# GD32E25x register map
File version: 1.0
CPU: CM23 r1p0, little endian, no MPU, no FPU, 2 interrupt priority bits
Registers are 32-bit, read-write, reset 0x0 unless marked. A register's access mark holds for its fields unless they carry their own. Offsets are from the block's base; [hi:lo] are bit positions.

## CMP — Comparator
Base 0x4001001C
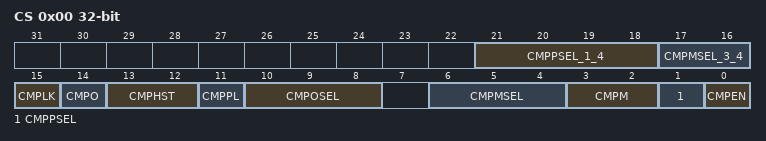
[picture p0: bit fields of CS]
0x00 CS access per field — control and status register
  [21:18] CMPPSEL_1_4 rw — CMP_IM input selection
  [17:16] CMPMSEL_3_4 rw — CMP_IP input selection
  [15] CMPLK rw — Comparator lock
  [14] CMPO ro — Comparator output
  [13:12] CMPHST rw — Comparator hysteresis
  [11] CMPPL rw — Polarity of comparator output
  [10:8] CMPOSEL rw — Comparator output selection
  [6:4] CMPMSEL rw — Comparator input selection
  [3:2] CMPM rw — Comparator mode
  [1] CMPPSEL rw — Comparator switch
  [0] CMPEN rw — Comparator enable

## CRC — cyclic redundancy check calculation unit
Base 0x40023000
0x00 DATA reset 0xFFFFFFFF
  [31:0] DATA — CRC calculation result bits
0x04 FDATA — Free data register
  [7:0] FDATA — General-purpose 8-bit data register bits
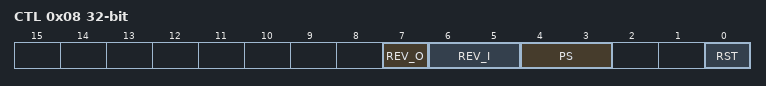
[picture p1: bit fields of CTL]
0x08 CTL — Control register
  [7] REV_O — Reverse output data
  [6:5] REV_I — Reverse input data
  [4:3] PS — Size of polynomial
  [0] RST — reset bit
0x10 IDATA reset 0xFFFFFFFF — Initialization Data Register
  [31:0] IDATA — CRC calculation initial value
0x14 POLY reset 0x4C11DB7 — Polynomial register
  [31:0] POLY — User configurable polynomial value

## DAC0 — Digital-to-analog converter
Base 0x40007400
Same registers: DAC1 0x4000CC00
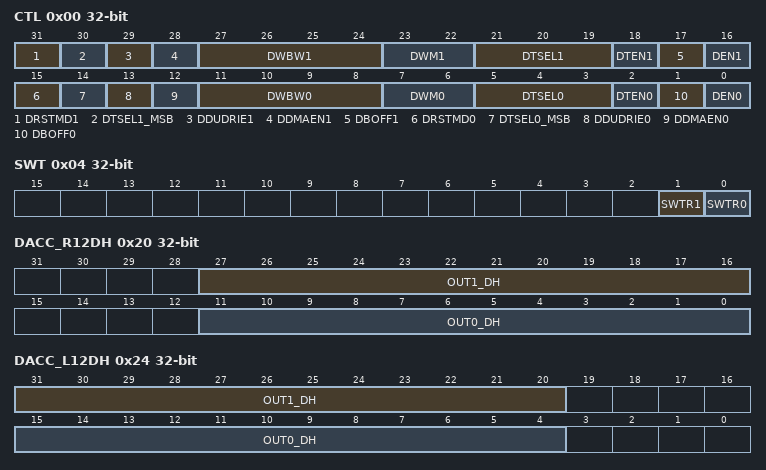
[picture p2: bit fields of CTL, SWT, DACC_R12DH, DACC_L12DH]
0x00 CTL — control register
  [31] DRSTMD1 — DAC1 Reset mode
  [30] DTSEL1_MSB — DAC1 Trigger selection bit3
  [29] DDUDRIE1 — DAC1 DMA underrun interrupt enable
  [28] DDMAEN1 — DAC1 DMA enable
  [27:24] DWBW1 — DAC1 noise wave bit width
  [23:22] DWM1 — DAC1 noise wave mode
  [21:19] DTSEL1 — DAC1 trigger selection
  [18] DTEN1 — DAC1 trigger enable
  [17] DBOFF1 — DAC1 output buffer turn off
  [16] DEN1 — DAC1 enable
  [15] DRSTMD0 — DAC0 Reset mode
  [14] DTSEL0_MSB — DAC0 Trigger selection bit3
  [13] DDUDRIE0 — DAC0 DMA underrun interrupt enable
  [12] DDMAEN0 — DAC0 DMA enable
  [11:8] DWBW0 — DAC0 noise wave bit width
  [7:6] DWM0 — DAC0 noise wave mode
  [5:3] DTSEL0 — DAC0 trigger selection
  [2] DTEN0 — DAC0 trigger enable
  [1] DBOFF0 — DAC0 output buffer turn off
  [0] DEN0 — DAC0 enable
0x04 SWT wo — software trigger register
  [1] SWTR1 — DAC1 software trigger
  [0] SWTR0 — DAC0 software trigger
0x08 OUT0_R12DH — DAC_OUT0 12-bit right-aligned data holding register
  [11:0] OUT0_DH — DACx_OUT0 12-bit right-aligned data
0x0C OUT0_L12DH — DAC_OUT0 12-bit left-aligned data holding register
  [15:4] OUT0_DH — DACx_OUT0 12-bit left-aligned data
0x10 OUT0_R8DH — DAC_OUT0 8-bit right aligned data holding register
  [7:0] OUT0_DH — DAC0 8-bit right-aligned data
0x14 OUT1_R12DH — DAC_OUT1 12-bit right-aligned data holding register
  [11:0] OUT1_DH — DACx_OUT1 12-bit right-aligned data
0x18 OUT1_L12DH — DAC_OUT1 12-bit left aligned data holding register
  [15:4] OUT1_DH — DACx_OUT1 12-bit left-aligned data
0x1C OUT1_R8DH — DACx_OUT1 8-bit right aligned data holding register
  [7:0] OUT1_DH — DACx_OUT1 8-bit right-aligned data
0x20 DACC_R12DH — DAC concurrent mode 12-bit right-aligned data holding register
  [27:16] OUT1_DH — DACx_OUT1 12-bit right-aligned data
  [11:0] OUT0_DH — DACx_OUT0 12-bit right-aligned data
0x24 DACC_L12DH — DAC concurrent mode 12-bit left aligned data holding register
  [31:20] OUT1_DH — DACx_OUT1 12-bit left-aligned data
  [15:4] OUT0_DH — DACx_OUT0 12-bit left-aligned data
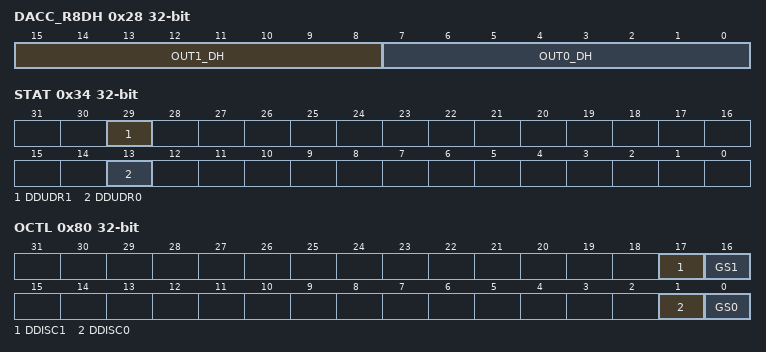
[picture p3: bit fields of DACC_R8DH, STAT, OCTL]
0x28 DACC_R8DH — DAC concurrent mode 8-bit right aligned data holding register
  [15:8] OUT1_DH — DACx_OUT1 8-bit right-aligned data
  [7:0] OUT0_DH — DACx_OUT0 8-bit right-aligned data
0x2C OUT0_DO ro — DAC_OUT0 data output register
  [11:0] OUT0_DO — DACx_OUT0 data output
0x30 OUT1_DO ro — DAC_OUT1 data output register
  [11:0] OUT1_DO — DACx_OUT1 data output
0x34 STAT — DAC status register
  [29] DDUDR1 — DACx_OUT1 DMA underrun flag
  [13] DDUDR0 — DACx_OUT0 DMA underrun flag
0x80 OCTL — DAC output control register
  [17] DDISC1 — DAC0_OUT1 connect GPIO selection
  [16] GS1 — DACx_OUT1 output buffer gain selection when DBOFF1=0
  [1] DDISC0 — DAC0_OUT0 connect GPIO selection
  [0] GS0 — DACx_OUT0 output buffer gain selection when DBOFF0=0
